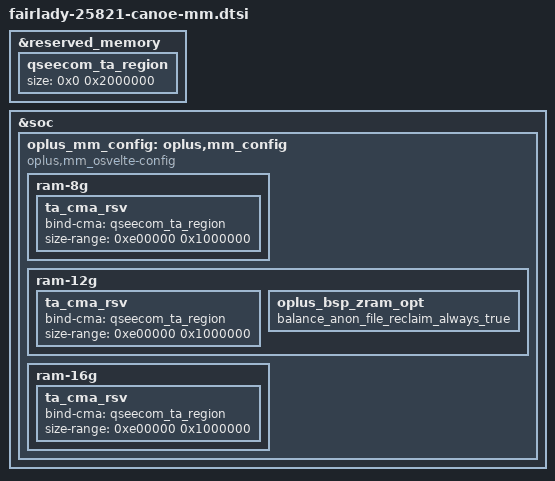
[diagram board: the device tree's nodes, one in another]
&reserved_memory {
  qseecom_ta_region {
    size = <0x0 0x2000000>;
  };
};

&soc {
  oplus_mm_config: oplus,mm_config {
    compatible = "oplus,mm_osvelte-config";
    ram-8g {
      /* 14M - 16M */
      ta_cma_rsv {
        bind-cma = "qseecom_ta_region";
        size-range = <0xe00000 0x1000000>;
      };
    };
    ram-12g {
      ta_cma_rsv {
        bind-cma = "qseecom_ta_region";
        size-range = <0xe00000 0x1000000>;
      };
      oplus_bsp_zram_opt {
        balance_anon_file_reclaim_always_true;
      };
    };
    ram-16g {
      ta_cma_rsv {
        bind-cma = "qseecom_ta_region";
        size-range = <0xe00000 0x1000000>;
      };
    };
  };
};
